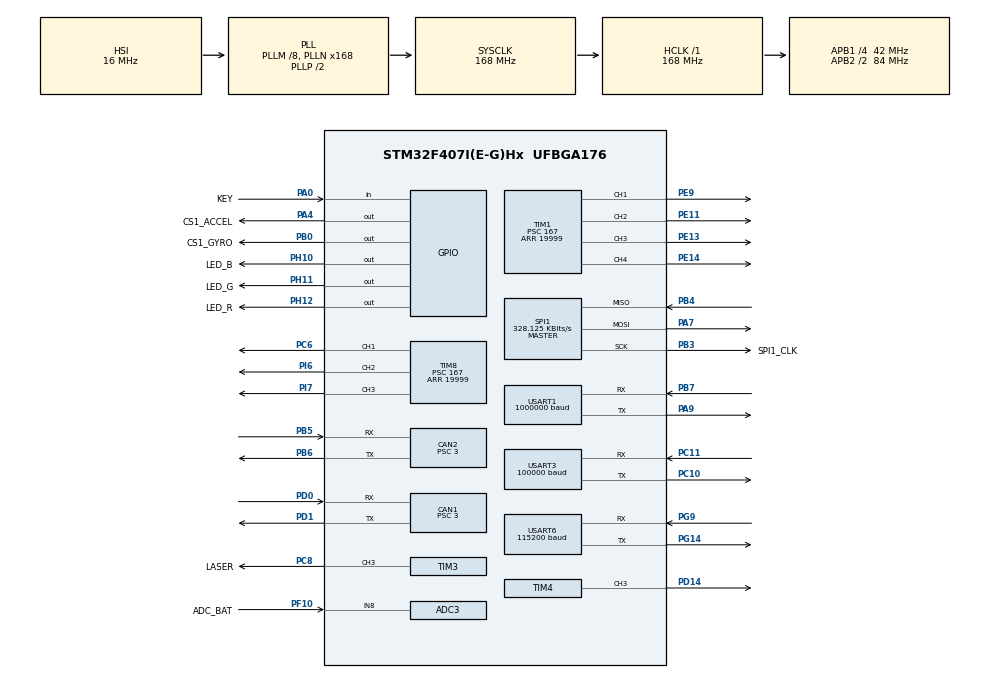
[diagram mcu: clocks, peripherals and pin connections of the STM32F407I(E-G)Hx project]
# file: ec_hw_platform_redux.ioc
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ADC3.Channel-0\#ChannelRegularConversion=ADC_CHANNEL_8
ADC3.Channel-IN8=ADC_CHANNEL_8
ADC3.ClockPrescaler=ADC_CLOCK_SYNC_PCLK_DIV6
ADC3.ContinuousConvMode=DISABLE
ADC3.DMAContinuousRequests=DISABLE
ADC3.DataAlign=ADC_DATAALIGN_RIGHT
ADC3.DiscontinuousConvMode=DISABLE
ADC3.EOCSelection=ADC_EOC_SINGLE_CONV
ADC3.EnableAnalogWatchDog=false
ADC3.ExternalTrigConv=ADC_EXTERNALTRIGCONV_T3_TRGO
ADC3.ExternalTrigConvEdge=ADC_EXTERNALTRIGCONVEDGE_RISING
ADC3.InjNumberOfConversion=0
ADC3.NbrOfConversion=1
ADC3.Rank-0\#ChannelRegularConversion=1
ADC3.Resolution=ADC_RESOLUTION_12B
ADC3.SamplingTime-0\#ChannelRegularConversion=ADC_SAMPLETIME_15CYCLES
ADC3.ScanConvMode=DISABLE
CAN1.ABOM=ENABLE
CAN1.BS1=CAN_BS1_10TQ
CAN1.BS2=CAN_BS2_3TQ
CAN1.CalculateBaudRate=1000000
CAN1.CalculateTimeBit=1000
CAN1.CalculateTimeQuantum=71.42857142857143
CAN1.NART=ENABLE
CAN1.Prescaler=3
CAN2.ABOM=ENABLE
CAN2.BS1=CAN_BS1_10TQ
CAN2.BS2=CAN_BS2_3TQ
CAN2.CalculateBaudRate=1000000
CAN2.CalculateTimeBit=1000
CAN2.CalculateTimeQuantum=71.42857142857143
CAN2.NART=ENABLE
CAN2.Prescaler=3
Dma.Request0=USART6_RX
Dma.Request1=USART6_TX
Dma.Request2=USART1_RX
Dma.Request3=USART1_TX
Dma.Request4=USART3_RX
Dma.USART1_RX.2.Direction=DMA_PERIPH_TO_MEMORY
Dma.USART1_RX.2.FIFOMode=DMA_FIFOMODE_DISABLE
Dma.USART1_RX.2.Instance=DMA2_Stream5
Dma.USART1_RX.2.MemDataAlignment=DMA_MDATAALIGN_BYTE
Dma.USART1_RX.2.MemInc=DMA_MINC_ENABLE
Dma.USART1_RX.2.Mode=DMA_NORMAL
Dma.USART1_RX.2.PeriphDataAlignment=DMA_PDATAALIGN_BYTE
Dma.USART1_RX.2.PeriphInc=DMA_PINC_DISABLE
Dma.USART1_RX.2.Priority=DMA_PRIORITY_MEDIUM
Dma.USART1_TX.3.Direction=DMA_MEMORY_TO_PERIPH
Dma.USART1_TX.3.FIFOMode=DMA_FIFOMODE_DISABLE
Dma.USART1_TX.3.Instance=DMA2_Stream7
Dma.USART1_TX.3.MemDataAlignment=DMA_MDATAALIGN_BYTE
Dma.USART1_TX.3.MemInc=DMA_MINC_ENABLE
Dma.USART1_TX.3.Mode=DMA_NORMAL
Dma.USART1_TX.3.PeriphDataAlignment=DMA_PDATAALIGN_BYTE
Dma.USART1_TX.3.PeriphInc=DMA_PINC_DISABLE
Dma.USART1_TX.3.Priority=DMA_PRIORITY_MEDIUM
Dma.USART3_RX.4.Direction=DMA_PERIPH_TO_MEMORY
Dma.USART3_RX.4.FIFOMode=DMA_FIFOMODE_DISABLE
Dma.USART3_RX.4.Instance=DMA1_Stream1
Dma.USART3_RX.4.MemDataAlignment=DMA_MDATAALIGN_BYTE
Dma.USART3_RX.4.MemInc=DMA_MINC_DISABLE
Dma.USART3_RX.4.Mode=DMA_NORMAL
Dma.USART3_RX.4.PeriphDataAlignment=DMA_PDATAALIGN_BYTE
Dma.USART3_RX.4.PeriphInc=DMA_PINC_DISABLE
Dma.USART3_RX.4.Priority=DMA_PRIORITY_HIGH
Dma.USART6_RX.0.Direction=DMA_PERIPH_TO_MEMORY
Dma.USART6_RX.0.FIFOMode=DMA_FIFOMODE_DISABLE
Dma.USART6_RX.0.Instance=DMA2_Stream1
Dma.USART6_RX.0.MemDataAlignment=DMA_MDATAALIGN_BYTE
Dma.USART6_RX.0.MemInc=DMA_MINC_ENABLE
Dma.USART6_RX.0.Mode=DMA_NORMAL
Dma.USART6_RX.0.PeriphDataAlignment=DMA_PDATAALIGN_BYTE
Dma.USART6_RX.0.PeriphInc=DMA_PINC_DISABLE
Dma.USART6_RX.0.Priority=DMA_PRIORITY_MEDIUM
Dma.USART6_TX.1.Direction=DMA_MEMORY_TO_PERIPH
Dma.USART6_TX.1.FIFOMode=DMA_FIFOMODE_DISABLE
Dma.USART6_TX.1.Instance=DMA2_Stream6
Dma.USART6_TX.1.MemDataAlignment=DMA_MDATAALIGN_BYTE
Dma.USART6_TX.1.MemInc=DMA_MINC_ENABLE
Dma.USART6_TX.1.Mode=DMA_NORMAL
Dma.USART6_TX.1.PeriphDataAlignment=DMA_PDATAALIGN_BYTE
Dma.USART6_TX.1.PeriphInc=DMA_PINC_DISABLE
Dma.USART6_TX.1.Priority=DMA_PRIORITY_MEDIUM
IWDG.Prescaler=IWDG_PRESCALER_32
IWDG.Reload=1500
Mcu.Family=STM32F4
Mcu.Name=STM32F407I(E-G)Hx
Mcu.Package=UFBGA176
NVIC.ADC_IRQn=true\:0\:0\:false\:false\:true\:true\:true\:true
NVIC.CAN1_RX0_IRQn=true\:0\:0\:false\:false\:true\:true\:true\:true
NVIC.CAN2_RX0_IRQn=true\:0\:0\:false\:false\:true\:true\:true\:true
NVIC.CAN2_RX1_IRQn=true\:0\:0\:false\:false\:true\:true\:true\:true
NVIC.DMA1_Stream1_IRQn=true\:5\:0\:true\:false\:true\:false\:true\:true
NVIC.DMA2_Stream1_IRQn=true\:0\:0\:false\:false\:true\:false\:true\:true
NVIC.DMA2_Stream5_IRQn=true\:0\:0\:false\:false\:true\:false\:true\:true
NVIC.DMA2_Stream6_IRQn=true\:0\:0\:false\:false\:true\:false\:true\:true
NVIC.DMA2_Stream7_IRQn=true\:0\:0\:false\:false\:true\:false\:true\:true
NVIC.PriorityGroup=NVIC_PRIORITYGROUP_4
NVIC.TIM5_IRQn=true\:0\:0\:false\:false\:true\:true\:true\:true
NVIC.TIM6_DAC_IRQn=true\:0\:0\:true\:false\:true\:true\:true\:true
NVIC.TIM7_IRQn=true\:0\:0\:false\:false\:true\:true\:true\:true
NVIC.USART1_IRQn=true\:0\:0\:false\:false\:true\:true\:true\:true
NVIC.USART3_IRQn=true\:0\:0\:false\:false\:true\:true\:true\:true
NVIC.USART6_IRQn=true\:0\:0\:false\:false\:true\:true\:true\:true
PA0-WKUP.GPIO_Label=KEY
PA0-WKUP.GPIO_PuPd=GPIO_PULLUP
PA0-WKUP.Signal=GPIO_Input
PA13.Mode=Serial_Wire
PA13.Signal=SYS_JTMS-SWDIO
PA14.Mode=Serial_Wire
PA14.Signal=SYS_JTCK-SWCLK
PA4.GPIO_Label=CS1_ACCEL
PA4.GPIO_PuPd=GPIO_PULLUP
PA4.GPIO_Speed=GPIO_SPEED_FREQ_HIGH
PA4.PinState=GPIO_PIN_SET
PA4.Signal=GPIO_Output
PA7.GPIO_PuPd=GPIO_PULLUP
PA7.Mode=Full_Duplex_Master
PA7.Signal=SPI1_MOSI
PA9.Mode=Asynchronous
PA9.Signal=USART1_TX
PB0.GPIO_Label=CS1_GYRO
PB0.GPIO_PuPd=GPIO_PULLUP
PB0.GPIO_Speed=GPIO_SPEED_FREQ_HIGH
PB0.PinState=GPIO_PIN_SET
PB0.Signal=GPIO_Output
PB3.GPIO_Label=SPI1_CLK
PB3.GPIO_PuPd=GPIO_PULLUP
PB3.Mode=Full_Duplex_Master
PB3.Signal=SPI1_SCK
PB4.GPIO_PuPd=GPIO_PULLUP
PB4.Mode=Full_Duplex_Master
PB4.Signal=SPI1_MISO
PB5.Mode=CAN_Activate
PB5.Signal=CAN2_RX
PB6.Mode=CAN_Activate
PB6.Signal=CAN2_TX
PB7.Mode=Asynchronous
PB7.Signal=USART1_RX
PC10.GPIO_PuPd=GPIO_PULLUP
PC10.Mode=Asynchronous
PC10.Signal=USART3_TX
PC11.GPIO_PuPd=GPIO_PULLUP
PC11.Mode=Asynchronous
PC11.Signal=USART3_RX
PC14-OSC32_IN.Mode=LSE-External-Oscillator
PC14-OSC32_IN.Signal=RCC_OSC32_IN
PC15-OSC32_OUT.Mode=LSE-External-Oscillator
PC15-OSC32_OUT.Signal=RCC_OSC32_OUT
PC6.Signal=S_TIM8_CH1
PC8.GPIO_Label=LASER
PC8.Signal=S_TIM3_CH3
PD0.Mode=CAN_Activate
PD0.Signal=CAN1_RX
PD1.Mode=CAN_Activate
PD1.Signal=CAN1_TX
PD14.Signal=S_TIM4_CH3
PE11.Signal=S_TIM1_CH2
PE13.Signal=S_TIM1_CH3
PE14.Signal=S_TIM1_CH4
PE9.Signal=S_TIM1_CH1
PF10.GPIO_Label=ADC_BAT
PF10.Mode=IN8
PF10.Signal=ADC3_IN8
PG14.GPIO_PuPd=GPIO_PULLUP
PG14.Mode=Asynchronous
PG14.Signal=USART6_TX
PG9.GPIO_PuPd=GPIO_PULLUP
PG9.Mode=Asynchronous
PG9.Signal=USART6_RX
PH0-OSC_IN.Mode=HSE-External-Oscillator
PH0-OSC_IN.Signal=RCC_OSC_IN
PH1-OSC_OUT.Mode=HSE-External-Oscillator
PH1-OSC_OUT.Signal=RCC_OSC_OUT
PH10.GPIO_Label=LED_B
PH10.Signal=GPIO_Output
PH11.GPIO_Label=LED_G
PH11.Signal=GPIO_Output
PH12.GPIO_Label=LED_R
PH12.Signal=GPIO_Output
PI6.Signal=S_TIM8_CH2
PI7.Signal=S_TIM8_CH3
ProjectManager.HeapSize=0x1000
ProjectManager.StackSize=0x2000
ProjectManager.TargetToolchain=MDK-ARM V5.32
RCC.48MHZClocksFreq_Value=84000000
RCC.AHBFreq_Value=168000000
RCC.APB1CLKDivider=RCC_HCLK_DIV4
RCC.APB1Freq_Value=42000000
RCC.APB1TimFreq_Value=84000000
RCC.APB2CLKDivider=RCC_HCLK_DIV2
RCC.APB2Freq_Value=84000000
RCC.APB2TimFreq_Value=168000000
RCC.CortexFreq_Value=168000000
RCC.FLatency=FLASH_LATENCY_5
RCC.HCLKFreq_Value=168000000
RCC.HSE_VALUE=25000000
RCC.HSI_VALUE=16000000
RCC.PLLM=8
RCC.PLLN=168
RCC.SYSCLKFreq_VALUE=168000000
RCC.SYSCLKSource=RCC_SYSCLKSOURCE_PLLCLK
RCC.VCOOutputFreq_Value=336000000
SH.S_TIM1_CH1.0=TIM1_CH1,PWM Generation1 CH1
SH.S_TIM1_CH2.0=TIM1_CH2,PWM Generation2 CH2
SH.S_TIM1_CH3.0=TIM1_CH3,PWM Generation3 CH3
SH.S_TIM1_CH4.0=TIM1_CH4,PWM Generation4 CH4
SH.S_TIM3_CH3.0=TIM3_CH3,PWM Generation3 CH3
SH.S_TIM4_CH3.0=TIM4_CH3,PWM Generation3 CH3
SH.S_TIM8_CH1.0=TIM8_CH1,PWM Generation1 CH1
SH.S_TIM8_CH2.0=TIM8_CH2,PWM Generation2 CH2
SH.S_TIM8_CH3.0=TIM8_CH3,PWM Generation3 CH3
SPI1.BaudRatePrescaler=SPI_BAUDRATEPRESCALER_256
SPI1.CLKPhase=SPI_PHASE_2EDGE
SPI1.CLKPolarity=SPI_POLARITY_HIGH
SPI1.CRCCalculation=SPI_CRCCALCULATION_DISABLE
SPI1.CalculateBaudRate=328.125 KBits/s
SPI1.DataSize=SPI_DATASIZE_8BIT
SPI1.Direction=SPI_DIRECTION_2LINES
SPI1.FirstBit=SPI_FIRSTBIT_MSB
SPI1.Mode=SPI_MODE_MASTER
SPI1.NSS=SPI_NSS_SOFT
SPI1.TIMode=SPI_TIMODE_DISABLE
SPI1.VirtualType=VM_MASTER
TIM1.AutoReloadPreload=TIM_AUTORELOAD_PRELOAD_DISABLE
TIM1.AutomaticOutput=TIM_AUTOMATICOUTPUT_DISABLE
TIM1.BreakPolarity=TIM_BREAKPOLARITY_HIGH
TIM1.BreakState=TIM_BREAK_DISABLE
TIM1.Channel-PWM\ Generation1\ CH1=TIM_CHANNEL_1
TIM1.Channel-PWM\ Generation2\ CH2=TIM_CHANNEL_2
TIM1.Channel-PWM\ Generation3\ CH3=TIM_CHANNEL_3
TIM1.Channel-PWM\ Generation4\ CH4=TIM_CHANNEL_4
TIM1.ClockDivision=TIM_CLOCKDIVISION_DIV1
TIM1.CounterMode=TIM_COUNTERMODE_UP
TIM1.LockLevel=TIM_LOCKLEVEL_OFF
TIM1.OC1Preload_PWM=ENABLE
TIM1.OC2Preload_PWM=ENABLE
TIM1.OC3Preload_PWM=ENABLE
TIM1.OC4Preload_PWM=ENABLE
TIM1.OCFastMode_PWM-PWM\ Generation1\ CH1=TIM_OCFAST_DISABLE
TIM1.OCFastMode_PWM-PWM\ Generation2\ CH2=TIM_OCFAST_DISABLE
TIM1.OCFastMode_PWM-PWM\ Generation3\ CH3=TIM_OCFAST_DISABLE
TIM1.OCFastMode_PWM-PWM\ Generation4\ CH4=TIM_OCFAST_DISABLE
TIM1.OCIdleState_1=TIM_OCIDLESTATE_RESET
TIM1.OCIdleState_2=TIM_OCIDLESTATE_RESET
TIM1.OCIdleState_3=TIM_OCIDLESTATE_RESET
TIM1.OCIdleState_4=TIM_OCIDLESTATE_RESET
TIM1.OCMode_PWM-PWM\ Generation1\ CH1=TIM_OCMODE_PWM1
TIM1.OCMode_PWM-PWM\ Generation2\ CH2=TIM_OCMODE_PWM1
TIM1.OCMode_PWM-PWM\ Generation3\ CH3=TIM_OCMODE_PWM1
TIM1.OCMode_PWM-PWM\ Generation4\ CH4=TIM_OCMODE_PWM1
TIM1.OCPolarity_1=TIM_OCPOLARITY_HIGH
TIM1.OCPolarity_2=TIM_OCPOLARITY_HIGH
TIM1.OCPolarity_3=TIM_OCPOLARITY_HIGH
TIM1.OCPolarity_4=TIM_OCPOLARITY_HIGH
TIM1.OffStateIDLEMode=TIM_OSSI_DISABLE
TIM1.OffStateRunMode=TIM_OSSR_DISABLE
TIM1.Period=19999
TIM1.Prescaler=167
TIM1.Pulse-PWM\ Generation1\ CH1=0
TIM1.Pulse-PWM\ Generation2\ CH2=0
TIM1.Pulse-PWM\ Generation3\ CH3=0
TIM1.Pulse-PWM\ Generation4\ CH4=0
TIM1.RepetitionCounter=0
TIM1.TIM_MasterOutputTrigger=TIM_TRGO_RESET
TIM1.TIM_MasterSlaveMode=TIM_MASTERSLAVEMODE_DISABLE
TIM3.AutoReloadPreload=TIM_AUTORELOAD_PRELOAD_DISABLE
TIM3.Channel-PWM\ Generation3\ CH3=TIM_CHANNEL_3
TIM3.ClockDivision=TIM_CLOCKDIVISION_DIV1
TIM3.CounterMode=TIM_COUNTERMODE_UP
TIM3.OC3Preload_PWM=ENABLE
TIM3.OCFastMode_PWM-PWM\ Generation3\ CH3=TIM_OCFAST_DISABLE
TIM3.OCMode_PWM-PWM\ Generation3\ CH3=TIM_OCMODE_PWM1
TIM3.OCPolarity_3=TIM_OCPOLARITY_HIGH
TIM3.Period=8399
TIM3.Prescaler=0
TIM3.Pulse-PWM\ Generation3\ CH3=0
TIM3.TIM_MasterOutputTrigger=TIM_TRGO_UPDATE
TIM3.TIM_MasterSlaveMode=TIM_MASTERSLAVEMODE_DISABLE
TIM4.AutoReloadPreload=TIM_AUTORELOAD_PRELOAD_DISABLE
TIM4.Channel-PWM\ Generation3\ CH3=TIM_CHANNEL_3
TIM4.ClockDivision=TIM_CLOCKDIVISION_DIV1
TIM4.CounterMode=TIM_COUNTERMODE_UP
TIM4.OC3Preload_PWM=ENABLE
TIM4.OCFastMode_PWM-PWM\ Generation3\ CH3=TIM_OCFAST_DISABLE
TIM4.OCMode_PWM-PWM\ Generation3\ CH3=TIM_OCMODE_PWM1
TIM4.OCPolarity_3=TIM_OCPOLARITY_HIGH
TIM4.Period=65535
TIM4.Prescaler=167
TIM4.Pulse-PWM\ Generation3\ CH3=0
TIM4.TIM_MasterOutputTrigger=TIM_TRGO_RESET
TIM4.TIM_MasterSlaveMode=TIM_MASTERSLAVEMODE_DISABLE
TIM5.AutoReloadPreload=TIM_AUTORELOAD_PRELOAD_DISABLE
TIM5.ClockDivision=TIM_CLOCKDIVISION_DIV1
TIM5.CounterMode=TIM_COUNTERMODE_UP
TIM5.Period=4294967295
TIM5.Prescaler=0
TIM5.TIM_MasterOutputTrigger=TIM_TRGO_RESET
TIM5.TIM_MasterSlaveMode=TIM_MASTERSLAVEMODE_DISABLE
TIM6.AutoReloadPreload=TIM_AUTORELOAD_PRELOAD_DISABLE
TIM6.CounterMode=TIM_COUNTERMODE_UP
TIM6.Period=1000-1
TIM6.Prescaler=83
TIM6.TIM_MasterOutputTrigger=TIM_TRGO_RESET
TIM7.AutoReloadPreload=TIM_AUTORELOAD_PRELOAD_DISABLE
TIM7.CounterMode=TIM_COUNTERMODE_UP
TIM7.Period=1000
TIM7.Prescaler=83
TIM7.TIM_MasterOutputTrigger=TIM_TRGO_RESET
TIM8.AutoReloadPreload=TIM_AUTORELOAD_PRELOAD_DISABLE
TIM8.AutomaticOutput=TIM_AUTOMATICOUTPUT_DISABLE
TIM8.BreakPolarity=TIM_BREAKPOLARITY_HIGH
TIM8.BreakState=TIM_BREAK_DISABLE
TIM8.Channel-PWM\ Generation1\ CH1=TIM_CHANNEL_1
TIM8.Channel-PWM\ Generation2\ CH2=TIM_CHANNEL_2
TIM8.Channel-PWM\ Generation3\ CH3=TIM_CHANNEL_3
TIM8.ClockDivision=TIM_CLOCKDIVISION_DIV1
TIM8.CounterMode=TIM_COUNTERMODE_UP
TIM8.LockLevel=TIM_LOCKLEVEL_OFF
TIM8.OC1Preload_PWM=ENABLE
TIM8.OC2Preload_PWM=ENABLE
TIM8.OC3Preload_PWM=ENABLE
TIM8.OCFastMode_PWM-PWM\ Generation1\ CH1=TIM_OCFAST_DISABLE
TIM8.OCFastMode_PWM-PWM\ Generation2\ CH2=TIM_OCFAST_DISABLE
TIM8.OCFastMode_PWM-PWM\ Generation3\ CH3=TIM_OCFAST_DISABLE
TIM8.OCIdleState_1=TIM_OCIDLESTATE_RESET
TIM8.OCIdleState_2=TIM_OCIDLESTATE_RESET
TIM8.OCIdleState_3=TIM_OCIDLESTATE_RESET
TIM8.OCMode_PWM-PWM\ Generation1\ CH1=TIM_OCMODE_PWM1
TIM8.OCMode_PWM-PWM\ Generation2\ CH2=TIM_OCMODE_PWM1
TIM8.OCMode_PWM-PWM\ Generation3\ CH3=TIM_OCMODE_PWM1
TIM8.OCPolarity_1=TIM_OCPOLARITY_HIGH
TIM8.OCPolarity_2=TIM_OCPOLARITY_HIGH
TIM8.OCPolarity_3=TIM_OCPOLARITY_HIGH
TIM8.OffStateIDLEMode=TIM_OSSI_DISABLE
TIM8.OffStateRunMode=TIM_OSSR_DISABLE
TIM8.Period=19999
TIM8.Prescaler=167
TIM8.Pulse-PWM\ Generation1\ CH1=0
TIM8.Pulse-PWM\ Generation2\ CH2=0
TIM8.Pulse-PWM\ Generation3\ CH3=0
TIM8.RepetitionCounter=0
TIM8.TIM_MasterOutputTrigger=TIM_TRGO_RESET
TIM8.TIM_MasterSlaveMode=TIM_MASTERSLAVEMODE_DISABLE
USART1.BaudRate=1000000
USART1.Mode=MODE_TX_RX
USART1.OverSampling=UART_OVERSAMPLING_16
USART1.Parity=PARITY_NONE
USART1.StopBits=STOPBITS_1
USART1.VirtualMode=VM_ASYNC
USART1.WordLength=WORDLENGTH_8B
USART3.BaudRate=100000
USART3.Mode=MODE_RX
USART3.OverSampling=UART_OVERSAMPLING_16
USART3.Parity=PARITY_EVEN
USART3.StopBits=STOPBITS_1
USART3.VirtualMode=VM_ASYNC
USART3.WordLength=WORDLENGTH_9B
USART6.BaudRate=115200
USART6.Mode=MODE_TX_RX
USART6.OverSampling=UART_OVERSAMPLING_16
USART6.Parity=PARITY_NONE
USART6.StopBits=STOPBITS_1
USART6.VirtualMode=VM_ASYNC
USART6.WordLength=WORDLENGTH_8B
VP_IWDG_VS_IWDG.Mode=IWDG_Activate
VP_TIM1_VS_ClockSourceINT.Mode=Internal
VP_TIM3_VS_ClockSourceINT.Mode=Internal
VP_TIM4_VS_ClockSourceINT.Mode=Internal
VP_TIM5_VS_ClockSourceINT.Mode=Internal
VP_TIM6_VS_ClockSourceINT.Mode=Enable_Timer
VP_TIM7_VS_ClockSourceINT.Mode=Enable_Timer
board=custom

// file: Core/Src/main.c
/* USER CODE BEGIN Header */
/**
  ******************************************************************************
  * @file           : main.c
  * @brief          : Main program body
  ******************************************************************************
  * @attention
  *
  * Copyright (c) 2023 STMicroelectronics.
  * All rights reserved.
  *
  * This software is licensed under terms that can be found in the LICENSE file
  * in the root directory of this software component.
  * If no LICENSE file comes with this software, it is provided AS-IS.
  *
  ******************************************************************************
  */
/* USER CODE END Header */
#include "main.h"
#include "adc.h"
#include "can.h"
#include "dma.h"
#include "iwdg.h"
#include "spi.h"
#include "tim.h"
#include "usart.h"
#include "gpio.h"

/* USER CODE BEGIN Includes */
#include "..\..\interface\robot.h"
/* USER CODE END Includes */

/* USER CODE BEGIN PV */
uint8_t rx_buff_[100];
uint8_t flagg = 0;
/* USER CODE END PV */

void SystemClock_Config(void);

int main(void)
{

  /* MCU Configuration--------------------------------------------------------*/

  /* Reset of all peripherals, Initializes the Flash interface and the Systick. */
  HAL_Init();

  /* Configure the system clock */
  SystemClock_Config();

  /* Initialize all configured peripherals */
  MX_GPIO_Init();
  MX_DMA_Init();
  MX_TIM3_Init();
  MX_USART1_UART_Init();
  MX_USART6_UART_Init();
  MX_ADC3_Init();
  MX_CAN1_Init();
  MX_IWDG_Init();
  MX_SPI1_Init();
  MX_TIM1_Init();
  MX_TIM4_Init();
  MX_TIM5_Init();
  MX_TIM8_Init();
  MX_USART3_UART_Init();
  MX_TIM6_Init();
  MX_TIM7_Init();
  MX_CAN2_Init();
  /* USER CODE BEGIN 2 */
//  HAL_UARTEx_ReceiveToIdle_DMA(&huart3,rx_buff_,sizeof(rx_buff_));
  HAL_UART_Receive_IT(&huart3,rx_buff_,18);
  HAL_TIM_Base_Start_IT(&htim6);
  /* USER CODE END 2 */

  /* Infinite loop */
  while (1)
  {

  }
}

void SystemClock_Config(void)
{
  RCC_OscInitTypeDef RCC_OscInitStruct = {0};
  RCC_ClkInitTypeDef RCC_ClkInitStruct = {0};

  /** Configure the main internal regulator output voltage
  */
  __HAL_RCC_PWR_CLK_ENABLE();
  __HAL_PWR_VOLTAGESCALING_CONFIG(PWR_REGULATOR_VOLTAGE_SCALE1);

  /** Initializes the RCC Oscillators according to the specified parameters
  * in the RCC_OscInitTypeDef structure.
  */
  RCC_OscInitStruct.OscillatorType = RCC_OSCILLATORTYPE_HSI|RCC_OSCILLATORTYPE_LSI;
  RCC_OscInitStruct.HSIState = RCC_HSI_ON;
  RCC_OscInitStruct.HSICalibrationValue = RCC_HSICALIBRATION_DEFAULT;
  RCC_OscInitStruct.LSIState = RCC_LSI_ON;
  RCC_OscInitStruct.PLL.PLLState = RCC_PLL_ON;
  RCC_OscInitStruct.PLL.PLLSource = RCC_PLLSOURCE_HSI;
  RCC_OscInitStruct.PLL.PLLM = 8;
  RCC_OscInitStruct.PLL.PLLN = 168;
  RCC_OscInitStruct.PLL.PLLP = RCC_PLLP_DIV2;
  RCC_OscInitStruct.PLL.PLLQ = 4;
  if (HAL_RCC_OscConfig(&RCC_OscInitStruct) != HAL_OK)
  {
    Error_Handler();
  }

  /** Initializes the CPU, AHB and APB buses clocks
  */
  RCC_ClkInitStruct.ClockType = RCC_CLOCKTYPE_HCLK|RCC_CLOCKTYPE_SYSCLK
                              |RCC_CLOCKTYPE_PCLK1|RCC_CLOCKTYPE_PCLK2;
  RCC_ClkInitStruct.SYSCLKSource = RCC_SYSCLKSOURCE_PLLCLK;
  RCC_ClkInitStruct.AHBCLKDivider = RCC_SYSCLK_DIV1;
  RCC_ClkInitStruct.APB1CLKDivider = RCC_HCLK_DIV4;
  RCC_ClkInitStruct.APB2CLKDivider = RCC_HCLK_DIV2;

  if (HAL_RCC_ClockConfig(&RCC_ClkInitStruct, FLASH_LATENCY_5) != HAL_OK)
  {
    Error_Handler();
  }
}

void Error_Handler(void)
{
  __disable_irq();
  while (1)
  {
  }
}
